VERSION ""

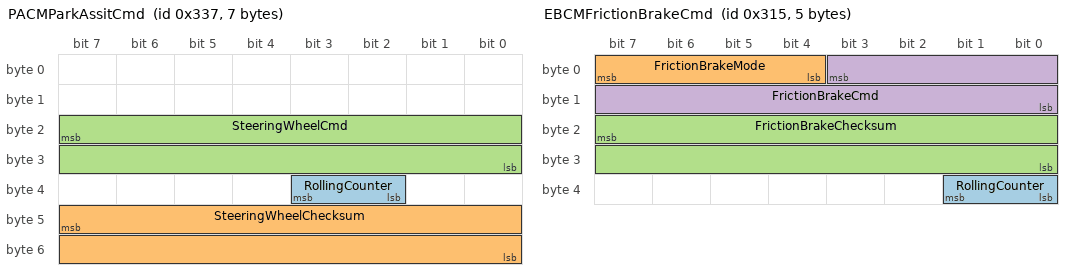
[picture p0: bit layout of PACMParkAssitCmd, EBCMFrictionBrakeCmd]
BO_ 823 PACMParkAssitCmd: 7 NEO
 SG_ RollingCounter : 35|2@0+ (1,0) [0|0] ""  NEO
 SG_ SteeringWheelChecksum : 47|16@0+ (1,0) [0|0] ""  NEO
 SG_ SteeringWheelCmd : 23|16@0+ (1,0) [0|0] ""  NEO

BO_ 560 EBCMRegen: 6 K17_EBCM
 SG_ Regen : 1|10@0+ (1,0) [0|0] ""  NEO

BO_ 368 EBCMFrictionBrakeStatus: 8 K17_EBCM
 SG_ FrictionBrakePressure : 23|16@0+ (1,0) [0|0] ""  NEO

BO_ 789 EBCMFrictionBrakeCmd: 5 K17_EBCM
 SG_ RollingCounter : 33|2@0+ (1,0) [0|0] ""  NEO
 SG_ FrictionBrakeMode : 7|4@0+ (1,0) [0|0] ""  NEO
 SG_ FrictionBrakeChecksum : 23|16@0+ (1,0) [0|0] ""  NEO
 SG_ FrictionBrakeCmd : 3|12@0- (1,0) [0|0] ""  NEO

BO_TX_BU_ 823 : K43_PSCM,NEO;
BO_TX_BU_ 789 : NEO,K17_EBCM;

CM_ SG_ 31 GEAR "13-P, 12-R, 11-N, 1-6-D";
